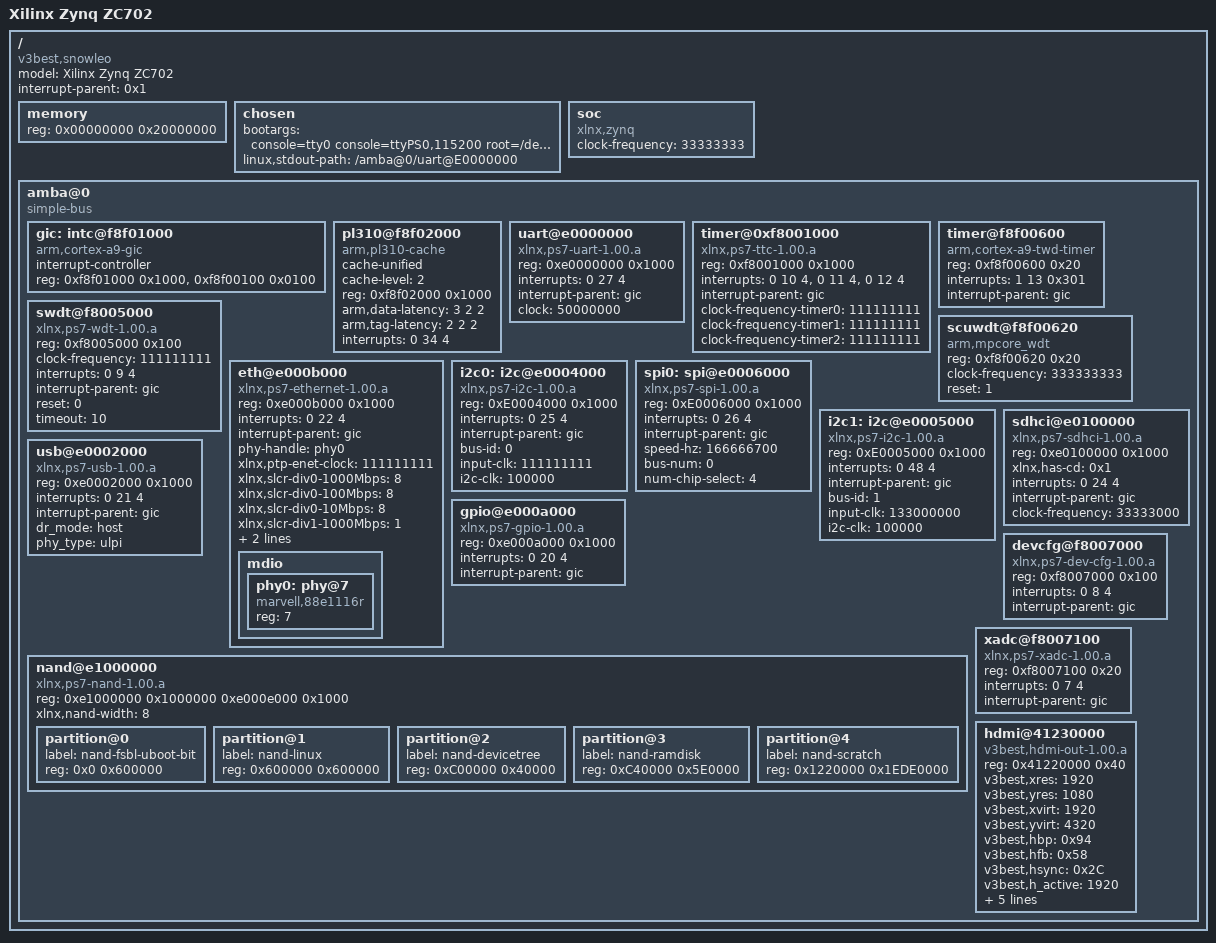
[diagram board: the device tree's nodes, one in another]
/dts-v1/;

/ {
	model = "Xilinx Zynq ZC702";
	compatible = "v3best,snowleo";
	#address-cells = <0x1>;
	#size-cells = <0x1>;
	interrupt-parent = <0x1>;

	memory {
		device_type = "memory";
		reg = <0x00000000 0x20000000>;
	};
	chosen {
		bootargs = "console=tty0 console=ttyPS0,115200 root=/dev/mmcblk0p2 rw
			ip=192.168.1.10:::255.255.255.0:ZC702:eth0 earlyprintk mem=384M
			memmap=64M$0x18000000 vmalloc=128M rootfstype=ext4 rootwait
			devtmpfs.mount=0 --no-log";
		linux,stdout-path = "/amba@0/uart@E0000000";
	};

	soc {
		compatible = "xlnx,zynq";
		clock-frequency = <33333333>;
	};

	amba@0 {
		compatible = "simple-bus";
		#address-cells = <0x1>;
		#size-cells = <0x1>;
		ranges;

		gic: intc@f8f01000 {
			interrupt-controller;
			compatible = "arm,cortex-a9-gic";
			#interrupt-cells = <3>;
			reg = < 0xf8f01000 0x1000 >,
			      < 0xf8f00100 0x0100 >;
		};

		pl310@f8f02000 {
			compatible = "arm,pl310-cache";
			cache-unified;
			cache-level = <2>;
			reg = <0xf8f02000 0x1000>;
			arm,data-latency = <3 2 2>;
			arm,tag-latency = <2 2 2>;
			interrupts = <0 34 4>;
		};

		uart@e0000000 {
			compatible = "xlnx,ps7-uart-1.00.a";
			reg = <0xe0000000 0x1000>;
			interrupts = < 0 27 4 >;
			interrupt-parent = <&gic>;
			clock = <50000000>;
		};

		timer@0xf8001000 {
			compatible = "xlnx,ps7-ttc-1.00.a";
			reg = <0xf8001000 0x1000>;
			interrupts = <0 10 4>,<0 11 4>,<0 12 4>;
			interrupt-parent = <&gic>;
			clock-frequency-timer0 = <111111111>;
			clock-frequency-timer1 = <111111111>;
			clock-frequency-timer2 = <111111111>;
		};

		timer@f8f00600 {
			compatible = "arm,cortex-a9-twd-timer";
			reg = <0xf8f00600 0x20>;
			interrupts = <1 13 0x301>;
			interrupt-parent = <&gic>;
		};

		swdt@f8005000 {
			device_type = "watchdog";
			compatible = "xlnx,ps7-wdt-1.00.a";
			reg = <0xf8005000 0x100>;
			clock-frequency = <111111111>;
			interrupts = <0 9 4>;
			interrupt-parent = <&gic>;
			reset = <0>;
			timeout = <10>;
		};

		scuwdt@f8f00620 {
			device_type = "watchdog";
			compatible = "arm,mpcore_wdt";
			reg = <0xf8f00620 0x20>;
			clock-frequency = <333333333>;
			reset = <1>;
		};

		eth@e000b000 {
			compatible = "xlnx,ps7-ethernet-1.00.a";
			reg = <0xe000b000 0x1000>;
			interrupts = <0 22 4>;
			interrupt-parent = <&gic>;
			phy-handle = <&phy0>;
			xlnx,ptp-enet-clock = <111111111>;
			xlnx,slcr-div0-1000Mbps = <8>;
			xlnx,slcr-div0-100Mbps = <8>;
			xlnx,slcr-div0-10Mbps = <8>;
			xlnx,slcr-div1-1000Mbps = <1>;
			xlnx,slcr-div1-100Mbps = <5>;
			xlnx,slcr-div1-10Mbps = <50>;
			#address-cells = <0x1>;
			#size-cells = <0x0>;
			mdio {
				#address-cells = <1>;
				#size-cells = <0>;
			phy0: phy@7 {
				compatible = "marvell,88e1116r";
				device_type = "ethernet-phy";
					reg = <7>;
				};
			};
		};

		i2c0: i2c@e0004000 {
			compatible = "xlnx,ps7-i2c-1.00.a";
			reg = <0xE0004000 0x1000>;
			interrupts = <0 25 4>;
			interrupt-parent = <&gic>;
			bus-id = <0>;
			input-clk = <111111111>;
			i2c-clk = <100000>;
		};

		spi0: spi@e0006000 {
			compatible = "xlnx,ps7-spi-1.00.a";
			reg = <0xE0006000 0x1000>;
			interrupts = <0 26 4>;
			interrupt-parent = <&gic>;
			speed-hz = <166666700>;
			bus-num = <0>;
			num-chip-select = <4>;

			#address-cells = <1>;
			#size-cells = <0>;
		};

		i2c1: i2c@e0005000 {
			compatible = "xlnx,ps7-i2c-1.00.a";
			reg = <0xE0005000 0x1000>;
			interrupts = < 0 48 4 >;
			interrupt-parent = <&gic>;
			bus-id = <1>;
			input-clk = <133000000>;
			i2c-clk = <100000>;

			#address-cells = <1>;
			#size-cells = <0>;
		};
		sdhci@e0100000 {
			compatible = "xlnx,ps7-sdhci-1.00.a";
			reg = <0xe0100000 0x1000>;
			xlnx,has-cd = <0x1>;
			interrupts = <0 24 4>;
			interrupt-parent = <&gic>;
			clock-frequency = <33333000>;
		};

		usb@e0002000 {
			compatible = "xlnx,ps7-usb-1.00.a";
			reg = <0xe0002000 0x1000>;
			interrupts = <0 21 4>;
			interrupt-parent = <&gic>;
			dr_mode = "host";
			//dr_mode = "peripheral";
			//dr_mode = "otg";
			phy_type = "ulpi";
		};

		gpio@e000a000 {
			compatible = "xlnx,ps7-gpio-1.00.a";
			reg = <0xe000a000 0x1000>;
			interrupts = <0 20 4>;
			interrupt-parent = <&gic>;
		};

		nand@e1000000 {
			compatible = "xlnx,ps7-nand-1.00.a";
			reg = <0xe1000000 0x1000000 0xe000e000 0x1000>;
			xlnx,nand-width = <8>;
			#address-cells = <0x1>;
			#size-cells = <0x1>;

			partition@0 {
				label = "nand-fsbl-uboot-bit";
				reg = <0x0 0x600000>;
				};

			partition@1 {
				label = "nand-linux";
				reg = <0x600000 0x600000>;
			};

			partition@2 {
				label = "nand-devicetree";
				reg = <0xC00000 0x40000>;
			};

			partition@3 {
				label = "nand-ramdisk";
				reg = <0xC40000 0x5E0000>;
			};

			partition@4 {
				label = "nand-scratch";
				reg = <0x1220000 0x1EDE0000>;
			};
		};
		devcfg@f8007000 {
			compatible = "xlnx,ps7-dev-cfg-1.00.a";
			reg = <0xf8007000 0x100>;
			interrupts = <0 8 4>;
			interrupt-parent = <&gic>;
		};
		xadc@f8007100 {
			compatible = "xlnx,ps7-xadc-1.00.a";
			reg = <0xf8007100 0x20>;
			interrupts = <0 7 4>;
			interrupt-parent = <&gic>;
		};

		hdmi@41230000 {
			compatible = "v3best,hdmi-out-1.00.a";
			reg = <0x41220000 0x40>;
			v3best,xres = <1920>;
			v3best,yres = <1080>;
			v3best,xvirt = <1920>;
			v3best,yvirt = <4320>;
			v3best,hbp = <0x94>;
			v3best,hfb = <0x58>;
			v3best,hsync = <0x2C>;
			v3best,h_active = <1920>;
			v3best,vbp = <0x24>;
			v3best,vfb = <0x04>;
			v3best,vsync = <0x05>;
			v3best,v_active = <1080>;

			v3best,fbphy = <0x18000000>;
			//interrupts = <0 7 4>;
			//interrupt-parent = <&gic>;
		};
	};
};
